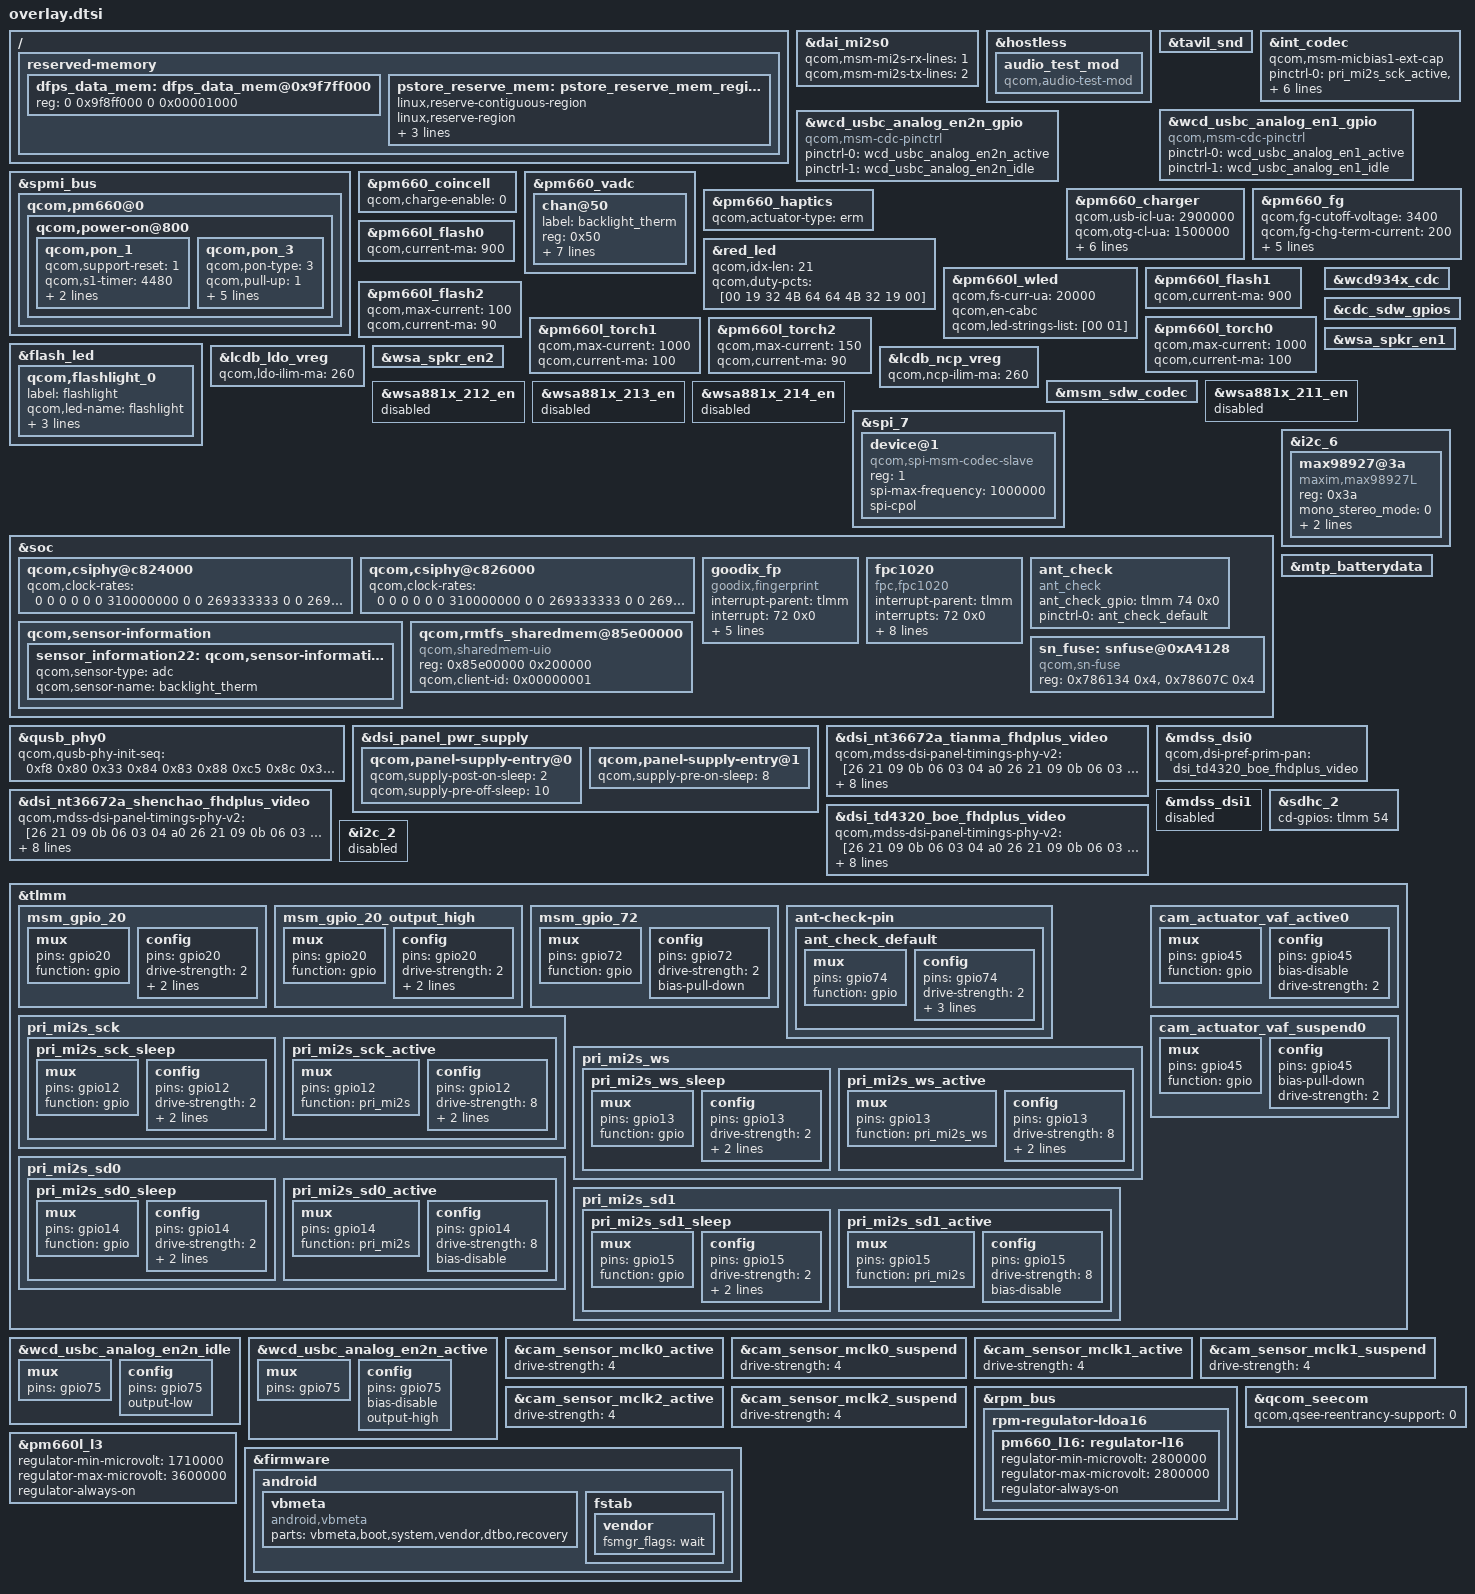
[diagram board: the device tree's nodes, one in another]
/*
 * Copyright (c) 2019 Xiaomi
 * lavender overlay based from xiaomi changes
 * by Rama Bondan Prakoso (rama982)
 */

/* msm-audio */
&dai_mi2s0 {
	qcom,msm-mi2s-rx-lines = <1>;
	qcom,msm-mi2s-tx-lines = <2>;
};

&hostless {
	audio_test_mod {
		compatible = "qcom,audio-test-mod";
	};
};

&tavil_snd {
	/delete-property/qcom,usbc-analog-en1_gpio;
	/delete-property/qcom,usbc-analog-en2_n_gpio;
};

&int_codec {
	qcom,msm-micbias1-ext-cap;
	/delete-property/qcom,msm-micbias2-ext-cap;
	/delete-property/qcom,us-euro-gpios;
	pinctrl-names = "pri_i2s_active", "pri_i2s_sleep";
	pinctrl-0 = <&pri_mi2s_sck_active &pri_mi2s_ws_active
			&pri_mi2s_sd0_active &pri_mi2s_sd1_active>;
	pinctrl-1 = <&pri_mi2s_sck_sleep &pri_mi2s_ws_sleep
			&pri_mi2s_sd0_sleep &pri_mi2s_sd1_sleep>;
};

&wcd_usbc_analog_en1_gpio {
	compatible = "qcom,msm-cdc-pinctrl";
	pinctrl-names = "aud_active", "aud_sleep";
	pinctrl-0 = <&wcd_usbc_analog_en1_active>;
	pinctrl-1 = <&wcd_usbc_analog_en1_idle>;
};

&wcd_usbc_analog_en2n_gpio {
	compatible = "qcom,msm-cdc-pinctrl";
	pinctrl-names = "aud_active", "aud_sleep";
	pinctrl-0 = <&wcd_usbc_analog_en2n_active>;
	pinctrl-1 = <&wcd_usbc_analog_en2n_idle>;
};

/* msm-pm660 */
&spmi_bus {
	qcom,pm660@0 {
		qcom,power-on@800 {
			qcom,pon_1 {
				qcom,support-reset = <1>;
				qcom,s1-timer = <4480>;
				qcom,s2-timer = <2000>;
				qcom,s2-type = <7>;
			};

			qcom,pon_3 {
				qcom,pon-type = <3>;
				qcom,pull-up = <1>;
				qcom,support-reset = <1>;
				qcom,s1-timer = <3072>;
				qcom,s2-timer = <2000>;
				qcom,s2-type = <1>;
				qcom,use-bark;
			};
		};
	};
};

&pm660_coincell {
	qcom,charge-enable = <0>;
};

&pm660_vadc {
	chan@50 {
		label = "backlight_therm";
		reg = <0x50>;
		qcom,decimation = <2>;
		qcom,pre-div-channel-scaling = <0>;
		qcom,calibration-type = "ratiometric";
		qcom,scale-function = <2>;
		qcom,hw-settle-time = <2>;
		qcom,fast-avg-setup = <0>;
		qcom,vadc-thermal-node;
	};
};

&pm660_charger {
	qcom,usb-icl-ua = <2900000>;
	qcom,otg-cl-ua = <1500000>;
	qcom,dc-icl-ua = <2900000>;
	qcom,fcc-max-ua = <2900000>;
	qcom,fv-max-uv  = <4400000>;
	qcom,sw-jeita-enable;
	qcom,thermal-mitigation
			= <2900000 2400000 2000000 1500000 800000 500000 100000>;
};

&pm660_fg {
	qcom,fg-cutoff-voltage = <3400>;
	qcom,fg-chg-term-current = <200>;
	qcom,fg-sys-term-current = <300>;
	qcom,fg-recharge-voltage = <4350>;
	qcom,fg-jeita-thresholds = <0 15 45 60>;
	qcom,fg-jeita-hyst-temp = <0>;
	qcom,battery-thermal-coefficients = [d2 50 ff];
};

&pm660_haptics {
	qcom,actuator-type = "erm";
};

/* msm-pm660l */
&red_led {
	qcom,idx-len = <21>;
	qcom,duty-pcts =
		[00 19 32 4B 64
		 64 4B 32 19 00];
};

&pm660l_wled {
 	qcom,fs-curr-ua = <20000>;
 	qcom,en-cabc;
 	/delete-property/qcom,auto-calibration-enable;
};

&pm660l_flash0 {
	qcom,current-ma = <900>;
};

&pm660l_flash1 {
	qcom,current-ma = <900>;
};

&pm660l_flash2 {
	qcom,max-current = <100>;
	qcom,current-ma = <90>;
};

&pm660l_torch0 {
	qcom,max-current = <1000>;
	qcom,current-ma = <100>;
};

&pm660l_torch1 {
	qcom,max-current = <1000>;
	qcom,current-ma = <100>;
};

&pm660l_torch2 {
	qcom,max-current = <150>;
	qcom,current-ma = <90>;
};

&flash_led {
	qcom,flashlight_0 {
		label = "flashlight";
		qcom,led-name = "flashlight";
		qcom,torch-name = "led:torch_0", "led:torch_1";
		qcom,switch-name = "led:switch_0";
		qcom,id = <0>;
	};
};

&lcdb_ldo_vreg {
	qcom,ldo-ilim-ma = <260>;
};

&lcdb_ncp_vreg {
	qcom,ncp-ilim-ma = <260>;
};

/* sdm660-audio */
&wcd934x_cdc {
	/delete-node/wcd_usbc_analog_en1_gpio;
	/delete-node/wcd_usbc_analog_en2n_gpio;
};

&cdc_sdw_gpios {
	/delete-property/pinctrl-names;
	/delete-property/pinctrl-0;
	/delete-property/pinctrl-1;
};

&wsa_spkr_en1 {
	/delete-property/pinctrl-names;
	/delete-property/pinctrl-0;
	/delete-property/pinctrl-1;
};

&wsa_spkr_en2 {
	/delete-property/pinctrl-names;
	/delete-property/pinctrl-0;
	/delete-property/pinctrl-1;
};

&msm_sdw_codec {
	/delete-property/qcom,cdc-sdw-gpios;
};

&wsa881x_211_en {
	status = "disabled";
};

&wsa881x_212_en {
	status = "disabled";
};

&wsa881x_213_en {
	status = "disabled";
};

&wsa881x_214_en {
	status = "disabled";
};

/* sdm660-blsp */
&spi_7 {
	status = "okay";
	device@1 {
		compatible = "qcom,spi-msm-codec-slave";
		#address-cells = <1>;
		#size-cells = <1>;
		reg = <1>; /* Chip select 0 */
		spi-max-frequency = <1000000>;
		spi-cpol;
	};
};

/* sdm660-camera-sensor-mtp */

#include "camera.dtsi"

/* sdm660-camera */
&soc {
	qcom,csiphy@c824000 {
		qcom,clock-rates = <0 0 0 0 0 0 310000000 0 0 269333333 0
			0 269000000 0 0>;
	};

	qcom,csiphy@c826000 {
		qcom,clock-rates = <0 0 0 0 0 0 310000000 0 0 269333333 0
			0 269000000 0 0>;
	};
};

/* sdm660-common */
&qusb_phy0 {
	qcom,qusb-phy-init-seq = <0xf8 0x80
				0x33 0x84
				0x83 0x88
				0xc5 0x8c
				0x30 0x08
				0x79 0x0c
				0x21 0x10
				0x14 0x9c
				0x9f 0x1c
				0x00 0x18>;
};

/* sdm660-internal-codec */
&int_codec {
	qcom,wsa-disable;
};

&i2c_6 { /* SmartPA TI */
	status = "okay";
	max98927@3a {
		compatible = "maxim,max98927L";
		status = "okay";
		reg = <0x3a>;
		mono_stereo_mode = <0>;
		interleave_mode = <0>;
		maxim,98927-reset-gpio = <&tlmm 77 0>;
	};
};

/* sdm660-mdss-panels */
#include "../dsi-panel-tianma-nt36672a-1080p-video.dtsi"
#include "../dsi-panel-shenchao-nt36672a-1080p-video.dtsi"
#include "../dsi-panel-boe-td4320-1080p-video.dtsi"

&dsi_panel_pwr_supply {
	qcom,panel-supply-entry@0 {
		qcom,supply-post-on-sleep = <2>;
		qcom,supply-pre-off-sleep = <10>;
	};

	qcom,panel-supply-entry@1 {
		qcom,supply-pre-on-sleep = <8>;
	};

};

&dsi_nt36672a_tianma_fhdplus_video {
        qcom,mdss-dsi-panel-timings-phy-v2 = [26 21 09 0b 06 03 04 a0
               26 21 09 0b 06 03 04 a0
               26 21 09 0b 06 03 04 a0
               26 21 09 0b 06 03 04 a0
               26 20 0a 0b 06 03 04 a0];
	qcom,mdss-dsi-min-refresh-rate = <48>;
        qcom,mdss-dsi-max-refresh-rate = <60>;
};

&dsi_nt36672a_shenchao_fhdplus_video {
        qcom,mdss-dsi-panel-timings-phy-v2 = [26 21 09 0b 06 03 04 a0
               26 21 09 0b 06 03 04 a0
               26 21 09 0b 06 03 04 a0
               26 21 09 0b 06 03 04 a0
               26 20 0a 0b 06 03 04 a0];
	qcom,mdss-dsi-min-refresh-rate = <48>;
        qcom,mdss-dsi-max-refresh-rate = <60>;
};

&dsi_td4320_boe_fhdplus_video {
        qcom,mdss-dsi-panel-timings-phy-v2 = [26 21 09 0b 06 03 04 a0
               26 21 09 0b 06 03 04 a0
               26 21 09 0b 06 03 04 a0
               26 21 09 0b 06 03 04 a0
               26 20 0a 0b 06 03 04 a0];
	qcom,mdss-dsi-min-refresh-rate = <48>;
        qcom,mdss-dsi-max-refresh-rate = <60>;
};

/* sdm660-mtp */
#include "novatek-i2c_f7a.dtsi"
#include "synaptics-tcm-i2c_f7a.dtsi"
&mtp_batterydata {
	/delete-node/qcom,itech_3000mah;
	/delete-node/qcom,ascent_3450mah;
	#include "battery/fg-gen3-batterydata-m6100atl-4000mah.dtsi"
	#include "battery/fg-gen3-batterydata-m6100sun-4000mah.dtsi"
	#include "battery/fg-gen3-batterydata-m6100default-4000mah.dtsi"
};

&mdss_dsi0 {
	qcom,dsi-pref-prim-pan = <&dsi_td4320_boe_fhdplus_video>;
};

&mdss_dsi1 {
	status = "disabled";
};

&pm660l_wled {
	qcom,led-strings-list = [00 01];
};

&dsi_nt36672a_tianma_fhdplus_video {
	qcom,mdss-dsi-bl-pmic-control-type = "bl_ctrl_wled";
	qcom,mdss-dsi-bl-min-level = <1>;
	qcom,mdss-dsi-bl-max-level = <4095>;
	qcom,panel-supply-entries = <&dsi_panel_pwr_supply>;
};

&dsi_nt36672a_shenchao_fhdplus_video {
	qcom,mdss-dsi-bl-pmic-control-type = "bl_ctrl_wled";
	qcom,mdss-dsi-bl-min-level = <1>;
	qcom,mdss-dsi-bl-max-level = <4095>;
	qcom,panel-supply-entries = <&dsi_panel_pwr_supply>;
};

&dsi_td4320_boe_fhdplus_video {
	qcom,mdss-dsi-bl-pmic-control-type = "bl_ctrl_wled";
	qcom,mdss-dsi-bl-min-level = <1>;
	qcom,mdss-dsi-bl-max-level = <4095>;
	qcom,panel-supply-entries = <&dsi_panel_pwr_supply>;
};

&sdhc_2 {
	cd-gpios = <&tlmm 54 0x0>;
};

&soc {
	goodix_fp {
		compatible = "goodix,fingerprint";
		interrupt-parent = <&tlmm>;
		interrupt = <72 0x0>;
		vcc_spi-supply = <&pm660l_l3>;
		vcc_ana-supply = <&pm660l_l3>;
		vdd_io-supply = <&pm660l_l3>;
		fp-gpio-irq = <&tlmm 72 0x00>;
		fp-gpio-reset = <&tlmm 20 0x00>;
		status = "okay";
	};

	fpc1020 {
		status = "ok";
		compatible = "fpc,fpc1020";
		interrupt-parent = <&tlmm>;
		interrupts = <72 0x0>;
		fpc,gpio_rst    = <&tlmm 20 0x0>;
		fpc,gpio_irq    = <&tlmm 72 0x0>;
		vcc_spi-supply  = <&pm660_l13>;
		vdd_io-supply   = <&pm660_l13>;
		vdd_ana-supply  = <&pm660_l13>;

		pinctrl-names = "fpc1020_reset_reset",
			"fpc1020_reset_active",
			"fpc1020_irq_active";

		pinctrl-0 = <&msm_gpio_20>;
		pinctrl-1 = <&msm_gpio_20_output_high>;
		pinctrl-2 = <&msm_gpio_72>;
	};

	ant_check {
		compatible = "ant_check";
	        ant_check_gpio = <&tlmm 74 0x0>;
		pinctrl-names = "default";
		pinctrl-0 = <&ant_check_default>;
	};
};
	
&i2c_2 {
	status = "disabled";
};

/* sdm660-pinctrl */
&tlmm {
	msm_gpio_20:msm_gpio_20 {
		mux{
			pins="gpio20";
			function= "gpio";
		};

		config {
			pins= "gpio20";
			drive-strength = <2>;
			bias-disable;
			output-low;
		};
	};

	msm_gpio_20_output_high:msm_gpio_20_output_high {
		mux {
			pins = "gpio20";
			function = "gpio";
		};

		config{
			pins = "gpio20";
			drive-strength = <2>;
			bias-disable;
			output-high;
		};
	};

	msm_gpio_72:msm_gpio_72{
		mux{
			pins = "gpio72";
			function = "gpio";
		};

		config{
			pins = "gpio72";
			drive-strength=<2>;
			bias-pull-down;
		};
	};

	ant-check-pin {
		ant_check_default: ant_check_default {
			mux {
				pins = "gpio74";
				function = "gpio";
			};

			config {
				pins = "gpio74";
				drive-strength = <2>;
				bias-disable;
				input-enable;
				input-debounce = <5000>;
			};
		};
	};


	/* add pri_mi2s for smartpa */
	pri_mi2s_sck {
		pri_mi2s_sck_sleep: pri_mi2s_sck_sleep {
			mux {
				pins = "gpio12";
				function = "gpio";
			};

			config {
				pins = "gpio12";
				drive-strength = <2>;   /* 2 mA */
				bias-pull-down;         /* PULL DOWN */
				input-enable;
			};
		};

		pri_mi2s_sck_active: pri_mi2s_sck_active {
			mux {
				pins = "gpio12";
				function = "pri_mi2s";
			};

			config {
				pins = "gpio12";
				drive-strength = <8>;   /* 8 mA */
				bias-disable;           /* NO PULL */
				output-high;
			};
		};
	};

	pri_mi2s_ws {
		pri_mi2s_ws_sleep: pri_mi2s_ws_sleep {
			mux {
				pins = "gpio13";
				function = "gpio";
			};

			config {
				pins = "gpio13";
				drive-strength = <2>;   /* 2 mA */
				bias-pull-down;         /* PULL DOWN */
				input-enable;
			};
		};

		pri_mi2s_ws_active: pri_mi2s_ws_active {
			mux {
				pins = "gpio13";
					function = "pri_mi2s_ws";
				};

			config {
				pins = "gpio13";
				drive-strength = <8>;   /* 8 mA */
				bias-disable;           /* NO PULL */
				output-high;
			};
		};
	};

	pri_mi2s_sd0 {
		pri_mi2s_sd0_sleep: pri_mi2s_sd0_sleep {
			mux {
				pins = "gpio14";
				function = "gpio";
			};

			config {
				pins = "gpio14";
				drive-strength = <2>;   /* 2 mA */
				bias-pull-down;         /* PULL DOWN */
				input-enable;
			};
		};

		pri_mi2s_sd0_active: pri_mi2s_sd0_active {
			mux {
				pins = "gpio14";
				function = "pri_mi2s";
			};

			config {
				pins = "gpio14";
				drive-strength = <8>;   /* 8 mA */
				bias-disable;           /* NO PULL */
			};
		};
	};

	pri_mi2s_sd1 {
		pri_mi2s_sd1_sleep: pri_mi2s_sd1_sleep {
			mux {
				pins = "gpio15";
				function = "gpio";
			};

			config {
				pins = "gpio15";
				drive-strength = <2>;   /* 2 mA */
				bias-pull-down;         /* PULL DOWN */
				input-enable;
			};
		};

		pri_mi2s_sd1_active: pri_mi2s_sd1_active {
			mux {
				pins = "gpio15";
				function = "pri_mi2s";
			};

			config {
				pins = "gpio15";
				drive-strength = <8>;   /* 8 mA */
				bias-disable;           /* NO PULL */
			};
		};
	};

	cam_actuator_vaf_active0: cam_actuator_vaf_active0 {
		/* ACTUATOR POWER */
		mux {
			pins = "gpio45";
			function = "gpio";
		};

		config {
			pins = "gpio45";
			bias-disable; /* No PULL */
			drive-strength = <2>; /* 2 MA */
		};
	};

	cam_actuator_vaf_suspend0: cam_actuator_vaf_suspend0 {
		/* ACTUATOR POWER */
		mux {
			pins = "gpio45";
			function = "gpio";
		};

		config {
			pins = "gpio45";
			bias-pull-down; /* PULL DOWN */
			drive-strength = <2>; /* 2 MA */
		};
	};
};

&wcd_usbc_analog_en2n_idle {
	mux {
		pins = "gpio75";
	};

	config {
		pins = "gpio75";
		/delete-property/output-high;
		output-low;
	};
};

&wcd_usbc_analog_en2n_active {
	mux {
		pins = "gpio75";
	};

	config {
		pins = "gpio75";
		/delete-property/bias-pull-down;
		/delete-property/output-low;
		bias-disable;
		output-high;
	};

};

&cam_sensor_mclk0_active {
	drive-strength = <4>; /* 2 MA */
};

&cam_sensor_mclk0_suspend {
	drive-strength = <4>; /* 2 MA */
};

&cam_sensor_mclk1_active {
	drive-strength = <4>; /* 2 MA */
};

&cam_sensor_mclk1_suspend {
	drive-strength = <4>; /* 2 MA */
};

&cam_sensor_mclk2_active {
	drive-strength = <4>; /* 2 MA */
};

&cam_sensor_mclk2_suspend {
	drive-strength = <4>; /* 2 MA */
};

/* sdm660-regulator */
&rpm_bus {
	rpm-regulator-ldoa16 {
		status = "okay";
		pm660_l16: regulator-l16 {
			regulator-min-microvolt = <2800000>;
			regulator-max-microvolt = <2800000>;
			status = "okay";
			regulator-always-on;
		};
	};
};

&pm660l_l3 {
	regulator-min-microvolt = <1710000>;
	regulator-max-microvolt = <3600000>;
	status = "okay";
	regulator-always-on;
};

/* sdm660 */
&firmware {
	android {
		vbmeta {
			compatible = "android,vbmeta";
			parts = "vbmeta,boot,system,vendor,dtbo,recovery";
		};
		fstab {
			vendor {
				fsmgr_flags = "wait";
			};
		};
	};
};

/ {
	reserved-memory {
		dfps_data_mem: dfps_data_mem@0x9f7ff000 {
		       reg = <0 0x9f8ff000 0 0x00001000>;
		};

		pstore_reserve_mem: pstore_reserve_mem_region@0 {
			linux,reserve-contiguous-region;
			linux,reserve-region;
			linux,remove-completely;
			reg = <0x0 0xA0000000 0x0 0x00400000>;
			label = "pstore_reserve_mem";
		};
	};
};

&soc {
	/delete-node/qcom,qbt1000;
	qcom,sensor-information {
		sensor_information22: qcom,sensor-information-22 {
			qcom,sensor-type = "adc";
			qcom,sensor-name = "backlight_therm";
		};
	};
	/delete-node/qcom,rmtfs_sharedmem@0;
	qcom,rmtfs_sharedmem@85e00000 {
		compatible = "qcom,sharedmem-uio";
		reg = <0x85e00000 0x200000>;
		reg-names = "rmtfs";
		qcom,client-id = <0x00000001>;

	};

	sn_fuse: snfuse@0xA4128 {
		compatible = "qcom,sn-fuse";
		reg = <0x786134 0x4>,
			<0x78607C 0x4>;
		reg-names = "sn-base","fuse-state";
	};
};

&qcom_seecom {
	qcom,qsee-reentrancy-support = <0>;
};

